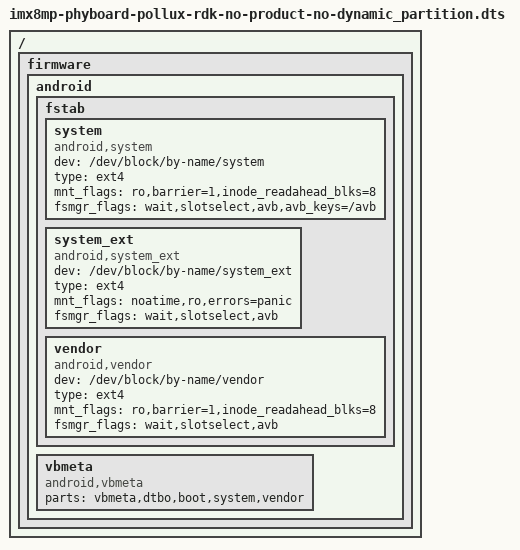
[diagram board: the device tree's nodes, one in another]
// SPDX-License-Identifier: GPL-2.0
/*
 * Copyright (C) 2021 PHYTEC Messtechnik GmbH
 * Author: Dominik Haller <d.haller@phytec.de>
 */

/dts-v1/;

#include "imx8mp-phyboard-pollux-rdk.dts"
/ {
	firmware {
		android {
			fstab {
				/delete-node/ product;
				system {
					compatible = "android,system";
					dev = "/dev/block/by-name/system";
					type = "ext4";
					mnt_flags = "ro,barrier=1,inode_readahead_blks=8";
					fsmgr_flags = "wait,slotselect,avb,avb_keys=/avb";
				};
				system_ext {
					compatible = "android,system_ext";
					dev = "/dev/block/by-name/system_ext";
					type = "ext4";
					mnt_flags = "noatime,ro,errors=panic";
					fsmgr_flags = "wait,slotselect,avb";
				};
				vendor {
					compatible = "android,vendor";
					dev = "/dev/block/by-name/vendor";
					type = "ext4";
					mnt_flags = "ro,barrier=1,inode_readahead_blks=8";
					fsmgr_flags = "wait,slotselect,avb";
				};
			};
			vbmeta {
				/*we need use FirstStageMountVBootV2 if we enable avb*/
				compatible = "android,vbmeta";
				/*parts means the partition which can be mount in first stage*/
				parts = "vbmeta,dtbo,boot,system,vendor";
			};
		};
	};
};
